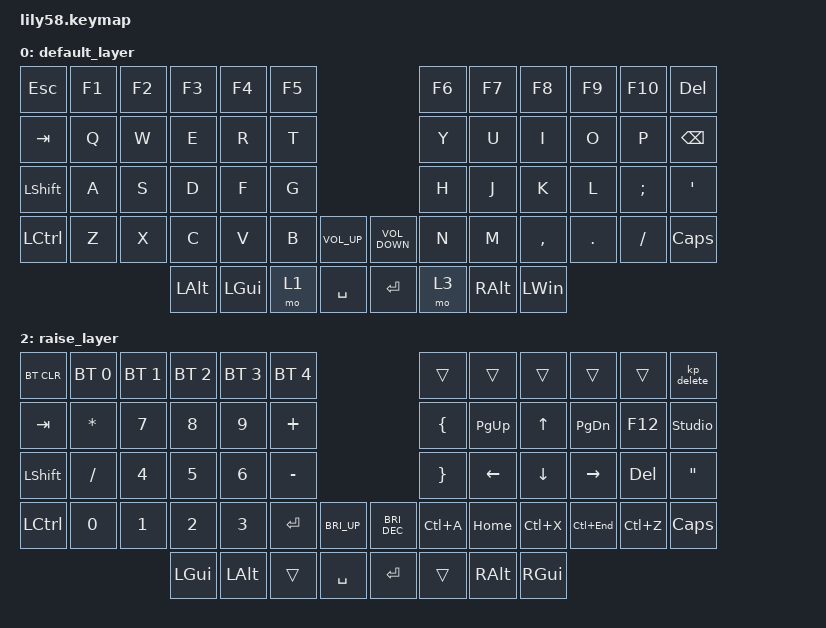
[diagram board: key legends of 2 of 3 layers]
/*
 * Copyright (c) 2020 The ZMK Contributors
 *
 * SPDX-License-Identifier: MIT
 */

#include <behaviors.dtsi>
#include <dt-bindings/zmk/keys.h>
#include <dt-bindings/zmk/bt.h>
#include <dt-bindings/zmk/ext_power.h>

/ {
    keymap {
        compatible = "zmk,keymap";

        default_layer {
// ------------------------------------------------------------------------------------------------------------
// |  ESC  | F1  |  F2 |  F3  |  F4  |  F5  |                    |  F6  |  F7   |  F8   |  F9  |  F10  | DELETE|
// |  TAB  |  Q  |  W  |  E   |  R   |  T   |                    |  Y   |  U    |  I    |  O   |   P   |  BSPC |
// | SHIFT |  A  |  S  |  D   |  F   |  G   |                    |  H   |  J    |  K    |  L   |   ;   |   '   |
// |  CTRL |  Z  |  X  |  C   |  V   |  B   |C_VOL_UP|  |C_VOL_DN|  N   |  M    |  ,    |  .   |   /   |  CAPS |
//                     | GUI  | ALT  | LOWER|  SPACE |  | ENTER  | RAISE|  ALT  | GUI   |
            bindings = <
&kp ESCAPE        &kp F1  &kp F2  &kp F3        &kp F4        &kp F5                                        &kp F6  &kp F7         &kp F8        &kp F9   &kp F10   &kp DELETE
&kp TAB           &kp Q   &kp W   &kp E         &kp R         &kp T                                         &kp Y   &kp U          &kp I         &kp O    &kp P     &kp BSPC
&kp LEFT_SHIFT    &kp A   &kp S   &kp D         &kp F         &kp G                                         &kp H   &kp J          &kp K         &kp L    &kp SEMI  &kp SQT
&kp LEFT_CONTROL  &kp Z   &kp X   &kp C         &kp V         &kp B   &kp C_VOLUME_UP    &kp C_VOLUME_DOWN  &kp N   &kp M          &kp COMMA     &kp DOT  &kp FSLH  &kp CAPS
                                  &kp LALT      &kp LGUI      &mo 1   &kp SPACE          &kp ENTER          &mo 3   &kp RIGHT_ALT  &kp LEFT_WIN
            >;

            sensor-bindings = <&inc_dec_kp C_VOL_UP C_VOL_DN &inc_dec_kp PG_UP PG_DN>;
        };

        lower_layer {
// ------------------------------------------------------------------------------------------------------------
// ------------------------------------------------------------------------------------------------------------
            // |       |  F1 |  F2 |  F3  |  F4  |  F5  |                   |  F6  |  F7   |  F8   |  F9  |      |  F11  |
            // |   `   |  *  |  7  |  8   |  9   |  +   |                   |     |  7    |  8    |  9   |   0   |  F12  |
            // |       |  /  |  4  |  5   |  6   |  -   |                   |  ^   |  &    |  *    |  (   |   )   |   |   |
            // |       |  0  |  1  |  2   |  3   |  =   |        |  |       |  [   |  ]    |  ;    |  :   |   \   |       |
            //               |     | GUI  | ALT  | LOWER| SPACE  |  | ENTER | RAISE|  ALT  | GUI   |      |

            bindings = <
&kp ESCAPE        &kp F1        &kp F2        &kp F3        &kp F4        &kp F5                                       &kp F6                &kp F7                 &kp F8           &kp F9     &studio_unlock    &kp kp_delete
&kp TAB           &kp ASTERISK  &kp N7        &kp N8        &kp N9        &kp PLUS                                     &kp LEFT_PARENTHESIS  &kp RIGHT_PARENTHESIS  &kp HOME         &kp END    &kp F11    &kp BSPC
&kp LEFT_SHIFT    &kp SLASH     &kp NUMBER_4  &kp N5        &kp NUMBER_6  &kp MINUS                                    &kp LEFT_BRACKET      &kp RIGHT_BRACKET      &kp PG_UP        &kp PG_DN  &kp PIPE   &kp DOUBLE_QUOTES
&kp LEFT_CONTROL  &kp N0        &kp N1        &kp NUMBER_2  &kp NUMBER_3  &kp EQUAL  &kp RA(F4)    &kp RC(RA(DELETE))  &kp LEFT_BRACE        &kp RIGHT_BRACE        &kp PRINTSCREEN  &kp GRAVE  &kp SLASH  &kp CAPSLOCK
                                &trans        &kp LEFT_GUI  &kp LEFT_ALT  &trans     &kp SPACE     &kp ENTER           &trans                &kp RIGHT_ALT          &kp RIGHT_GUI    &trans
            >;

            sensor-bindings = <&inc_dec_kp C_VOL_UP C_VOL_DN>;
        };

        raise_layer {
// ------------------------------------------------------------------------------------------------------------
// | BTCLR | BT1  | BT2  |  BT3  |  BT4  |  BT5 |                |      |      |       |      |       |  DEL  |
// |       | INS  | PSCR | GUI   |       |      |                |      | PGUP |   ^   | PGDN |       |  BSPC |
// |       | ALT  | CTRL | SHIFT |       | CAPS |                |      |   <- |   v   |  ->  |       |       |
// |       | UNDO | CUT  | COPY  | PASTE |      |      |  |      |      | HOME |       | END  |       |       |
//                |      |       |       |      |      |  |      |      |      |       |      |

            bindings = <
&bt BT_CLR        &bt BT_SEL 0  &bt BT_SEL 1  &bt BT_SEL 2  &bt BT_SEL 3  &bt BT_SEL 4                                        &trans           &trans         &trans         &trans         &trans     &kp_delete
&kp TAB           &kp ASTERISK  &kp N7        &kp N8        &kp N9        &kp PLUS                                            &kp LEFT_BRACE   &kp PAGE_UP    &kp UP         &kp PAGE_DOWN  &kp F12    &studio_unlock
&kp LEFT_SHIFT    &kp SLASH     &kp NUMBER_4  &kp N5        &kp NUMBER_6  &kp MINUS                                           &kp RIGHT_BRACE  &kp LEFT       &kp DOWN       &kp RIGHT      &kp DEL    &kp DOUBLE_QUOTES
&kp LEFT_CONTROL  &kp N0        &kp N1        &kp NUMBER_2  &kp NUMBER_3  &kp ENTER     &kp C_BRI_UP    &kp C_BRIGHTNESS_DEC  &kp LC(A)        &kp HOME       &kp LC(X)      &kp LC(END)    &kp LC(Z)  &kp CAPSLOCK
                                              &kp LEFT_GUI  &kp LEFT_ALT  &trans        &kp SPACE       &kp ENTER             &trans           &kp RIGHT_ALT  &kp RIGHT_GUI
            >;

            sensor-bindings = <&inc_dec_kp C_VOL_UP C_VOL_DN>;
        };
    };
};
